# SAMA7D65D4GN8 register map
Vendor: Microchip Technology; Series: SAMA7D6; File version: 0
Registers are 32-bit, read-write, reset 0x0 unless marked. A register's access mark holds for its fields unless they carry their own. Offsets are from the block's base; [hi:lo] are bit positions; lines under a group give offsets from that group; {n}, {i} and the like mark numbered series; 'fields as' and 'values as' point back to an identical list.

## TZC — TrustZone Address Space Controller (TZC)
Base 0xE3000000
0x04 SYS_ACTION — TZC_SYS Action Register
  [1:0] REACTION_VALUE — Failure Reaction
    0=NO_IT_AND_NO_BUS_ERROR (No interrupt line and no system bus error report); 1=NO_IT_BUT_BUS_ERROR (No interrupt triggered but bus error response); 2=IT_AND_NO_BUS_ERROR (Interrupt line and no system bus error report); 3=IT_AND_BUS_ERROR (Interrupt line and system bus error report)
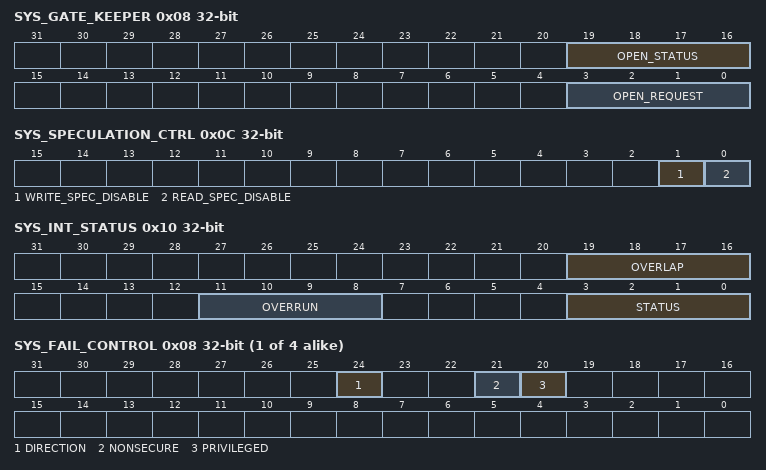
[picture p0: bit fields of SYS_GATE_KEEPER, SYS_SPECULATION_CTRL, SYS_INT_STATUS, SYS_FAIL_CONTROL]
0x08 SYS_GATE_KEEPER — TZC_SYS Gate Keeper Register
  [19:16] OPEN_STATUS — Gate Keeper Open Status (read-only)
  [3:0] OPEN_REQUEST — Gate Keeper Open Request
0x0C SYS_SPECULATION_CTRL — TZC_SYS Speculation Control Register
  [1] WRITE_SPEC_DISABLE — Write Speculation Disable Control
  [0] READ_SPEC_DISABLE — Read Speculation Disable Control
0x10 SYS_INT_STATUS ro — TZC_SYS Interrupt Status Register
  [19:16] OVERLAP — Interrupt Status Overlap
  [11:8] OVERRUN — Interrupt Status Overrun
  [3:0] STATUS — Interrupt Status
0x14 SYS_INT_CLEAR wo — TZC_SYS Interrupt Clear Register
  [3:0] CLEAR — Interrupt Clear
{0x20+0x10*i} TZC_SYS_FAIL[{i}] (i=0..3) group
  0x00 SYS_FAIL_ADDRESS ro — TZC_SYS Fail Address Register
    [31:0] FAIL_ADDRESS — Failure Access Address
  0x08 SYS_FAIL_CONTROL ro — TZC_SYS Fail Control Register
    [24] DIRECTION — Failure Access Direction
      0=READ_ACCESS; 1=WRITE_ACCESS
    [21] NONSECURE — Failure Access Security Value
    [20] PRIVILEGED — Failure Access Privileged Value
  0x0C SYS_FAIL_ID ro — TZC_SYS Fail ID Register
    [16:0] FAIL_ID — Failure Access ID
{0x100+0x20*i} TZC_SYS_REGION[{i}] (i=0..8) group
  0x00 SYS_REGION_BASE — TZC_SYS Region x Base Address Register
    [31:12] BASE_ADDRESS — Region y Base Address
  0x08 SYS_REGION_TOP reset 0xFFF — TZC_SYS Region x Top Address Register
    [31:12] TOP_ADDRESS — Region y Top Address
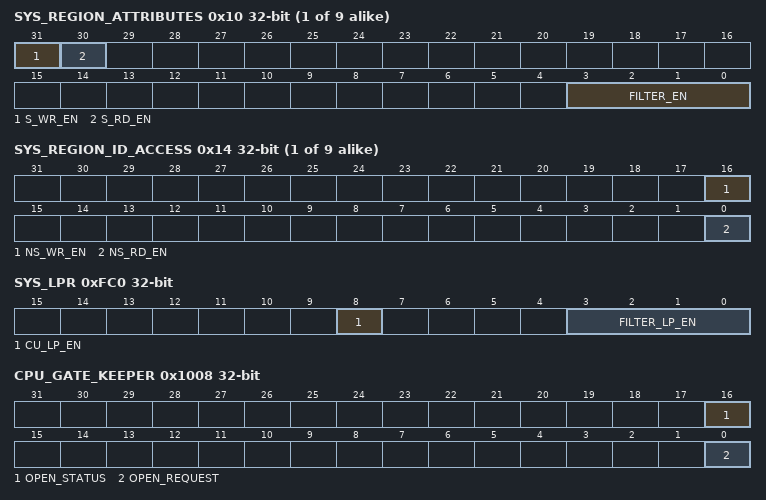
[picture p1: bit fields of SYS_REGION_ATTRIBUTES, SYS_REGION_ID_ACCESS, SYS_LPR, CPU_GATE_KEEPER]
  0x10 SYS_REGION_ATTRIBUTES — TZC_SYS Region x Attribute Register
    [31] S_WR_EN — Region y Secure Global Write Enable
    [30] S_RD_EN — Region y Secure Global Read Enable
    [3:0] FILTER_EN — Region y Filter Enable
  0x14 SYS_REGION_ID_ACCESS — TZC_SYS Region x ID Access Register
    [16] NS_WR_EN — Region y Non-Secure Global Write Enable
    [0] NS_RD_EN — Region y Non-Secure Global Read Enable
0xFC0 SYS_LPR — TZC_SYS Low-Power Register
  [8] CU_LP_EN — Control Unit Low-Power Enable
  [3:0] FILTER_LP_EN — Filter Low-Power Enable
0x1004 CPU_ACTION — TZC_CPU Action Register
  fields as SYS_ACTION
0x1008 CPU_GATE_KEEPER — TZC_CPU Gate Keeper Register
  [16] OPEN_STATUS — Gate Keeper Open Status (read-only)
  [0] OPEN_REQUEST — Gate Keeper Open Request
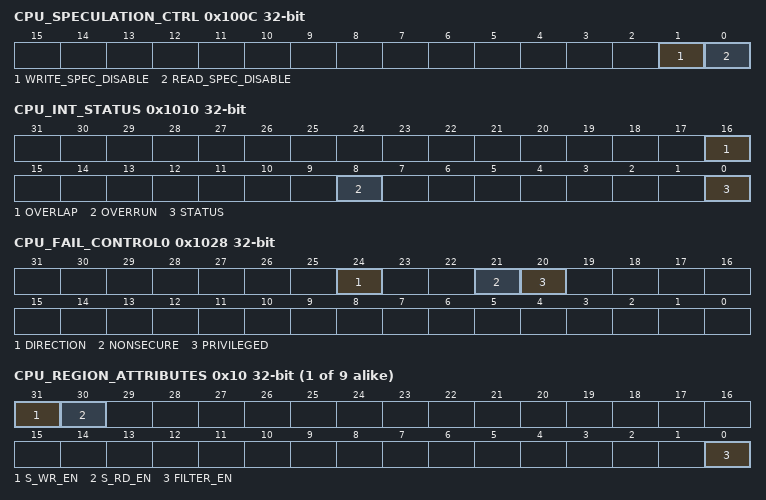
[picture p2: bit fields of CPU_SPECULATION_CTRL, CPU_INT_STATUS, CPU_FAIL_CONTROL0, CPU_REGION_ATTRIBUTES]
0x100C CPU_SPECULATION_CTRL — TZC_CPU Speculation Control Register
  fields as SYS_SPECULATION_CTRL
0x1010 CPU_INT_STATUS ro — TZC_CPU Interrupt Status Register
  [16] OVERLAP — Interrupt Status Overlap
  [8] OVERRUN — Interrupt Status Overrun
  [0] STATUS — Interrupt Status
0x1014 CPU_INT_CLEAR wo — TZC_CPU Interrupt Clear Register
  [0] CLEAR — Interrupt Clear
0x1020 CPU_FAIL_ADDRESS0 ro — TZC_CPU Fail Address Register 0
  [31:0] FAIL_ADDRESS — Failure Access Address
0x1028 CPU_FAIL_CONTROL0 ro — TZC_CPU Fail Control Register 0
  fields as TZC_SYS_FAIL[0].SYS_FAIL_CONTROL
0x102C CPU_FAIL_ID0 ro — TZC_CPU Fail ID Register 0
  [16:0] FAIL_ID — Failure Access ID
{0x1100+0x20*i} TZC_CPU_REGION[{i}] (i=0..8) group
  0x00 CPU_REGION_BASE — TZC_CPU Region x Base Address Register
    [31:12] BASE_ADDRESS — Region y Base Address
  0x08 CPU_REGION_TOP reset 0xFFF — TZC_CPU Region x Top Address Register
    [31:12] TOP_ADDRESS — Region y Top Address
  0x10 CPU_REGION_ATTRIBUTES — TZC_CPU Region x Attribute Register
    [31] S_WR_EN — Region y Secure Global Write Enable
    [30] S_RD_EN — Region y Secure Global Read Enable
    [0] FILTER_EN — Region y Filter Enable
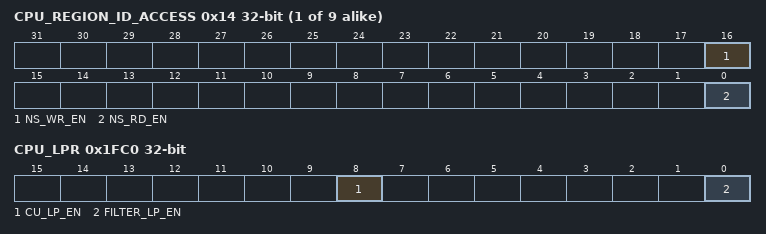
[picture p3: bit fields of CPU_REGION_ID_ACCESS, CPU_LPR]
  0x14 CPU_REGION_ID_ACCESS — TZC_CPU Region x ID Access Register
    [16] NS_WR_EN — Region y 0 Non-Secure Global Write Enable
    [0] NS_RD_EN — Region y Non-Secure Global Read Enable
0x1FC0 CPU_LPR — TZC_CPU Low-Power Register
  [8] CU_LP_EN — Control Unit Low-Power Enable
  [0] FILTER_LP_EN — Filter Low-Power Enable
